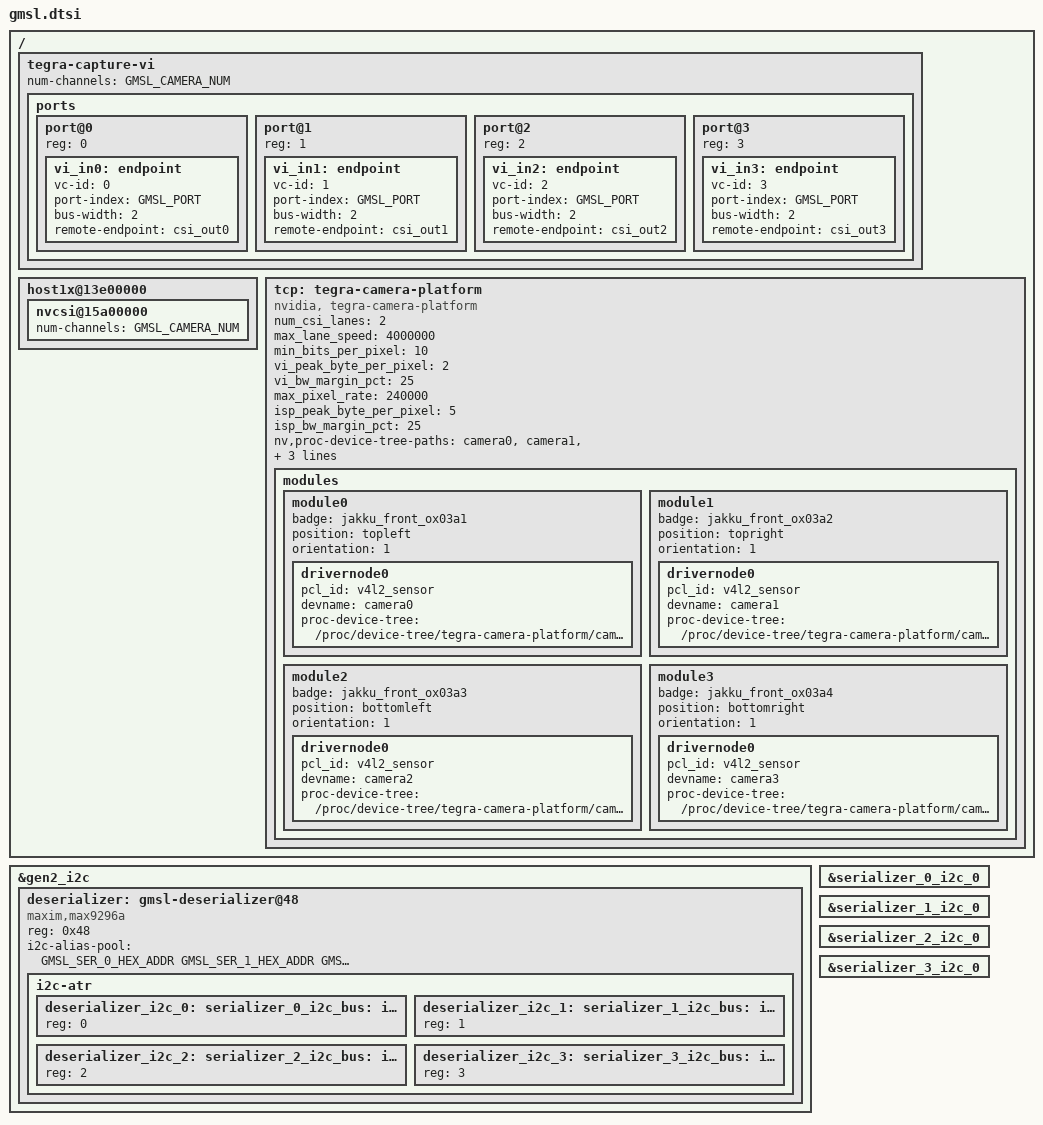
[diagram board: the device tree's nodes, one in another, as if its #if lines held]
/*
 * Copyright (c) 2018-2020, NVIDIA CORPORATION.  All rights reserved.
 *
 * This program is free software; you can redistribute it and/or modify
 * it under the terms of the GNU General Public License as published by
 * the Free Software Foundation; either version 2 of the License, or
 * (at your option) any later version.
 *
 * This program is distributed in the hope that it will be useful, but WITHOUT
 * ANY WARRANTY; without even the implied warranty of MERCHANTABILITY or
 * FITNESS FOR A PARTICULAR PURPOSE.  See the GNU General Public License for
 * more details.
 *
 * You should have received a copy of the GNU General Public License
 * along with this program.  If not, see <http://www.gnu.org/licenses/>.
 */
#include <dt-bindings/media/camera.h>

// #define GMSL_USE_I2C_BUS_2
// #define GMSL_USE_I2C_BUS_8
// #define GMSL_USE_I2C_MUX_BUS
// #define GMSL_LANE_POLARITY_SWAP
// #define GMSL_USE_PORT_1
// #define GMSL_USE_PORT_2

#define _CONCAT(a, b) a ## b
#define CONCAT(a, b) _CONCAT(a, b)

#define _STRINGIFY(a) # a
#define STRINGIFY(a) _STRINGIFY(a)

#define GMSL_CAMERA_NUM	4

// #define GMSL_DESER_MAX9296A
// #define GMSL_SER_0_MAX9295A
// #define GMSL_SER_1_MAX9295A

#ifdef GMSL_DESER_MAX9296A

#if GMSL_CAMERA_NUM > 2
#undef GMSL_CAMERA_NUM
#define GMSL_CAMERA_NUM 2
#endif

#endif

#if (GMSL_CAMERA_NUM >= 1)
#define GMSL_CAMERA_0
#endif
#if (GMSL_CAMERA_NUM >= 2)
#define GMSL_CAMERA_1
#endif
#if (GMSL_CAMERA_NUM >= 3)
#define GMSL_CAMERA_2
#endif
#if (GMSL_CAMERA_NUM >= 4)
#define GMSL_CAMERA_3
#endif

#ifdef GMSL_DESER_MAX9296A
#define GMSL_PHY		0x1
#else
#define GMSL_PHY		0x2
#endif

#if defined(GMSL_USE_PORT_1)
#define GMSL_PORT		0x1
#define GMSL_PORT_SERIAL	"serial_b"
#elif defined(GMSL_USE_PORT_2)
#define GMSL_PORT		0x2
#define GMSL_PORT_SERIAL	"serial_c"
#else
#define GMSL_PORT		0x0
#define GMSL_PORT_SERIAL	"serial_a"
#endif

#define GMSL_MIPI_DT		0x2c
#define GMSL_MIPI_DT_FS		0x0
#define GMSL_MIPI_DT_FE		0x1

#define GMSL_SER_0_HEX_ADDR	0x41
#define GMSL_SER_1_HEX_ADDR	0x42
#define GMSL_SER_2_HEX_ADDR	0x43
#define GMSL_SER_3_HEX_ADDR	0x44

#define GMSL_CAM_0_HEX_ADDR	0x37
#define GMSL_CAM_1_HEX_ADDR	0x38
#define GMSL_CAM_2_HEX_ADDR	0x39
#define GMSL_CAM_3_HEX_ADDR	0x3a

/ {
	tegra-capture-vi  {
		num-channels = <GMSL_CAMERA_NUM>;

		ports {
			#address-cells = <1>;
			#size-cells = <0>;

#if defined(GMSL_CAMERA_0)
			port@0 {
				reg = <0>;

				vi_in0: endpoint {
					vc-id = <0>;
					port-index = <GMSL_PORT>;
					bus-width = <2>;
					remote-endpoint = <&csi_out0>;
				};
			};
#endif

#if defined(GMSL_CAMERA_1)
			port@1 {
				reg = <1>;

				vi_in1: endpoint {
					vc-id = <1>;
					port-index = <GMSL_PORT>;
					bus-width = <2>;
					remote-endpoint = <&csi_out1>;
				};
			};
#endif

#if defined(GMSL_CAMERA_2)
			port@2 {
				reg = <2>;

				vi_in2: endpoint {
					vc-id = <2>;
					port-index = <GMSL_PORT>;
					bus-width = <2>;
					remote-endpoint = <&csi_out2>;
				};
			};
#endif

#if defined(GMSL_CAMERA_3)
			port@3 {
				reg = <3>;

				vi_in3: endpoint {
					vc-id = <3>;
					port-index = <GMSL_PORT>;
					bus-width = <2>;
					remote-endpoint = <&csi_out3>;
				};
			};
#endif
		};
	};

	host1x@13e00000 {
		nvcsi@15a00000 {
			num-channels = <GMSL_CAMERA_NUM>;

			#address-cells = <1>;
			#size-cells = <0>;

#if defined(GMSL_CAMERA_0)
			#define NVCSI_CH_INDEX 0
			#include "gmsl-nvcsi-channel.dtsi"
#endif

#if defined(GMSL_CAMERA_1)
			#define NVCSI_CH_INDEX 1
			#include "gmsl-nvcsi-channel.dtsi"
#endif

#if defined(GMSL_CAMERA_2)
			#define NVCSI_CH_INDEX 2
			#include "gmsl-nvcsi-channel.dtsi"
#endif

#if defined(GMSL_CAMERA_3)
			#define NVCSI_CH_INDEX 3
			#include "gmsl-nvcsi-channel.dtsi"
#endif
		};
	};
};

#if defined(GMSL_USE_I2C_BUS_2)
deserializer_i2c_bus: &gen2_i2c {};
#elif defined(GMSL_USE_I2C_BUS_8)
deserializer_i2c_bus: &gen8_i2c {};
#elif defined(GMSL_USE_I2C_MUX_BUS)
deserializer_i2c_bus: &cam_i2c {};
#else
/ {
	cam_i2cmux {
		deserializer_i2c_bus: i2c@0 {};
	};
};
#endif

&deserializer_i2c_bus {
	#ifdef GMSL_DESER_MAX9296A
	deserializer: gmsl-deserializer@48 {
	#else
	deserializer: gmsl-deserializer@27 {
	#endif
		#address-cells = <1>;
		#size-cells = <0>;

		#ifdef GMSL_DESER_MAX9296A
		compatible = "maxim,max9296a";
		#else
		compatible = "maxim,max96724";
		#endif
		#ifdef GMSL_DESER_MAX9296A
		reg = <0x48>;
		#else
		reg = <0x27>;
		#endif
	};
};

&deserializer {
#if defined(GMSL_CAMERA_0)
	#define DESER_CH_INDEX 0
	#include "gmsl-deserializer-channel.dtsi"
#endif

#if defined(GMSL_CAMERA_1)
	#define DESER_CH_INDEX 1
	#include "gmsl-deserializer-channel.dtsi"
#endif

#if defined(GMSL_CAMERA_2)
	#define DESER_CH_INDEX 2
	#include "gmsl-deserializer-channel.dtsi"
#endif

#if defined(GMSL_CAMERA_3)
	#define DESER_CH_INDEX 3
	#include "gmsl-deserializer-channel.dtsi"
#endif
};

&deserializer {
	i2c-alias-pool = <
		GMSL_SER_0_HEX_ADDR
		GMSL_SER_1_HEX_ADDR
		GMSL_SER_2_HEX_ADDR
		GMSL_SER_3_HEX_ADDR
	>;

	i2c-atr {
		#address-cells = <1>;
		#size-cells = <0>;

#if defined(GMSL_CAMERA_0)
		deserializer_i2c_0: i2c@0 {
			#address-cells = <1>;
			#size-cells = <0>;

			reg = <0>;
		};
#endif

#if defined(GMSL_CAMERA_1)
		deserializer_i2c_1: i2c@1 {
			#address-cells = <1>;
			#size-cells = <0>;

			reg = <1>;
		};
#endif

#if defined(GMSL_CAMERA_2)
		deserializer_i2c_2: i2c@2 {
			#address-cells = <1>;
			#size-cells = <0>;

			reg = <2>;
		};
#endif

#if defined(GMSL_CAMERA_3)
		deserializer_i2c_3: i2c@3 {
			#address-cells = <1>;
			#size-cells = <0>;

			reg = <3>;
		};
#endif
	};
};

#if defined(GMSL_CAMERA_0)
serializer_0_i2c_bus: &deserializer_i2c_0 {};
#endif
#if defined(GMSL_CAMERA_1)
serializer_1_i2c_bus: &deserializer_i2c_1 {};
#endif
#if defined(GMSL_CAMERA_2)
serializer_2_i2c_bus: &deserializer_i2c_2 {};
#endif
#if defined(GMSL_CAMERA_3)
serializer_3_i2c_bus: &deserializer_i2c_3 {};
#endif

#if defined(GMSL_CAMERA_0)
&serializer_0_i2c_bus {
	#define SER_INDEX 0
	#define SER_I2C_ADDR_POLL_0 GMSL_CAM_0_HEX_ADDR
	#ifdef GMSL_SER_0_MAX9295A
	#define SER_COMPAT "maxim,max9295a"
	#endif
	#include "gmsl-serializer.dtsi"
};
#endif

#if defined(GMSL_CAMERA_1)
&serializer_1_i2c_bus {
	#define SER_INDEX 1
	#define SER_I2C_ADDR_POLL_0 GMSL_CAM_1_HEX_ADDR
	#ifdef GMSL_SER_1_MAX9295A
	#define SER_COMPAT "maxim,max9295a"
	#endif
	#include "gmsl-serializer.dtsi"
};
#endif

#if defined(GMSL_CAMERA_2)
&serializer_2_i2c_bus {
	#define SER_INDEX 2
	#define SER_I2C_ADDR_POLL_0 GMSL_CAM_2_HEX_ADDR
	#include "gmsl-serializer.dtsi"
};
#endif

#if defined(GMSL_CAMERA_3)
&serializer_3_i2c_bus {
	#define SER_INDEX 3
	#define SER_I2C_ADDR_POLL_0 GMSL_CAM_3_HEX_ADDR
	#include "gmsl-serializer.dtsi"
};
#endif

#if defined(GMSL_CAMERA_0)
camera_0_i2c_bus: &serializer_0_i2c_0 {};
#endif
#if defined(GMSL_CAMERA_1)
camera_1_i2c_bus: &serializer_1_i2c_0 {};
#endif
#if defined(GMSL_CAMERA_2)
camera_2_i2c_bus: &serializer_2_i2c_0 {};
#endif
#if defined(GMSL_CAMERA_3)
camera_3_i2c_bus: &serializer_3_i2c_0 {};
#endif

#if defined(GMSL_CAMERA_0)
&camera_0_i2c_bus {
	#define OX03A_INDEX 0
	#include "gmsl-ox03a.dtsi"
};
#endif

#if defined(GMSL_CAMERA_1)
&camera_1_i2c_bus {
	#define OX03A_INDEX 1
	#include "gmsl-ox03a.dtsi"
};
#endif

#if defined(GMSL_CAMERA_2)
&camera_2_i2c_bus {
	#define OX03A_INDEX 2
	#include "gmsl-ox03a.dtsi"
};
#endif

#if defined(GMSL_CAMERA_3)
&camera_3_i2c_bus {
	#define OX03A_INDEX 3
	#include "gmsl-ox03a.dtsi"
};
#endif

/ {
	tcp: tegra-camera-platform {
		compatible = "nvidia, tegra-camera-platform";
		/**
		* Physical settings to calculate max ISO BW
		*
		* num_csi_lanes = <>;
		* Total number of CSI lanes when all cameras are active
		*
		* max_lane_speed = <>;
		* Max lane speed in Kbit/s
		*
		* min_bits_per_pixel = <>;
		* Min bits per pixel
		*
		* vi_peak_byte_per_pixel = <>;
		* Max byte per pixel for the VI ISO case
		*
		* vi_bw_margin_pct = <>;
		* Vi bandwidth margin in percentage
		*
		* max_pixel_rate = <>;
		* Max pixel rate in Kpixel/s for the ISP ISO case
		*
		* isp_peak_byte_per_pixel = <>;
		* Max byte per pixel for the ISP ISO case
		*
		* isp_bw_margin_pct = <>;
		* Isp bandwidth margin in percentage
		*/
		num_csi_lanes = <2>;
		max_lane_speed = <4000000>;
		min_bits_per_pixel = <10>;
		vi_peak_byte_per_pixel = <2>;
		vi_bw_margin_pct = <25>;
		max_pixel_rate = <240000>;
		isp_peak_byte_per_pixel = <5>;
		isp_bw_margin_pct = <25>;

		nv,proc-device-tree-paths =
			"camera0",
			"camera1",
			"camera2",
			"camera3";
		nv,proc-device-tree-targets = <
			&camera0
			&camera1
			&camera2
			&camera3>;

		/**
		 * The general guideline for naming badge_info contains 3 parts, and is as follows,
		 * The first part is the camera_board_id for the module; if the module is in a FFD
		 * platform, then use the platform name for this part.
		 * The second part contains the position of the module, ex. "rear" or "front".
		 * The third part contains the last 6 characters of a part number which is found
		 * in the module's specsheet from the vendor.
		 */
#if defined(GMSL_CAMERA_0)
		modules {
			module0 {
				badge = "jakku_front_ox03a1";
				position = "topleft";
				orientation = "1";
				drivernode0 {
					pcl_id = "v4l2_sensor";
					devname = "camera0";
					proc-device-tree = "/proc/device-tree/tegra-camera-platform/camera0";
				};
			};
#endif

#if defined(GMSL_CAMERA_1)
			module1 {
				badge = "jakku_front_ox03a2";
				position = "topright";
				orientation = "1";
				drivernode0 {
					pcl_id = "v4l2_sensor";
					devname = "camera1";
					proc-device-tree = "/proc/device-tree/tegra-camera-platform/camera1";
				};
			};
#endif

#if defined(GMSL_CAMERA_2)
			module2 {
				badge = "jakku_front_ox03a3";
				position = "bottomleft";
				orientation = "1";
				drivernode0 {
					pcl_id = "v4l2_sensor";
					devname = "camera2";
					proc-device-tree = "/proc/device-tree/tegra-camera-platform/camera2";
				};
			};
#endif

#if defined(GMSL_CAMERA_3)
			module3 {
				badge = "jakku_front_ox03a4";
				position = "bottomright";
				orientation = "1";
				drivernode0 {
					pcl_id = "v4l2_sensor";
					devname = "camera3";
					proc-device-tree = "/proc/device-tree/tegra-camera-platform/camera3";
				};
			};
#endif
		};
	};
};

#undef STRINGIFY
#undef _STRINGIFY

#undef CONCAT
#undef _CONCAT
